# STM32L496AEI6 register map
File version: 1.0
Registers are 32-bit, access not given, reset 0x0 unless marked. A register's access mark holds for its fields unless they carry their own. Offsets are from the block's base; [hi:lo] are bit positions; {n}, {i} and the like mark numbered series; 'fields as' and 'values as' point back to an identical list.

## SAI1
Base 0x40015400
Same registers: SAI2 0x40015800
0x00 GCR
  [5:4] SYNCOUT, [31:2] s, [1:0] SYNCIN
0x04 CR1A
  [23:20] MCKDIV, [19] NODIV, [17] DMAEN, [16] SAIEN, [13] OUTDRIV, [12] MONO, [11:10] SYNCEN, [9] CKSTR, [8] LSBFIRST, [7:5] DS, [31:4] s, [3:2] PRTCFG, [1:0] MODE
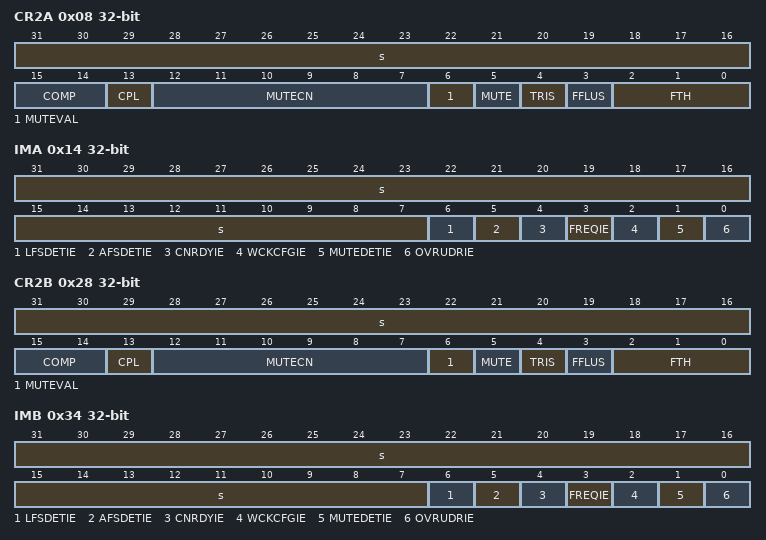
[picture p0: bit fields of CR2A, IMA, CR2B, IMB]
0x08 CR2A
  [31:16] s, [15:14] COMP, [13] CPL, [12:7] MUTECN, [6] MUTEVAL, [5] MUTE, [4] TRIS, [3] FFLUS, [2:0] FTH
0x0C FRCRA
  [18] FSOFF, [17] FSPOL, [16] FSDEF, [31:15] s, [14:8] FSALL, [7:0] FRL
0x10 SLOTRA
  [31:16] SLOTEN, [11:8] NBSLOT, [7:6] SLOTSZ, [15:5] s, [4:0] FBOFF
0x14 IMA
  [31:7] s, [6] LFSDETIE, [5] AFSDETIE, [4] CNRDYIE, [3] FREQIE, [2] WCKCFGIE, [1] MUTEDETIE, [0] OVRUDRIE
0x18 SRA
  [18:16] FLVL, [31:7] s, [6] LFSDET, [5] AFSDET, [4] CNRDY, [3] FREQ, [2] WCKCFG, [1] MUTEDET, [0] OVRUDR
0x1C CLRFRA
  [6] CLFSDET, [5] CAFSDET, [4] CCNRDY, [31:3] s, [2] CWCKCFG, [1] CMUTEDET, [0] COVRUDR
0x20 DRA
  [31:0] DATA
0x24 CR1B
  fields as CR1A
0x28 CR2B
  fields as CR2A
0x2C FRCRB
  fields as FRCRA
0x30 SLOTRB
  [31:16] SLOTEN, [11:8] NBSLOT, [7:6] SLOTSZ, [15:5] s, [4:0] FBOFF
0x34 IMB
  fields as IMA
0x38 SRB
  fields as SRA
0x3C CLRFRB
  fields as CLRFRA
0x40 DRB
  [31:0] DATA

## DFSDM1
Base 0x40016000
0x00 CH0CFGR1
  [31] DFSDMEN, [30] CKOUTSRC, [23:16] CKOUTDIV, [15:14] DATPACK, [13:12] DATMPX, [8] CHINSEL, [7] CHEN, [6] CKABEN, [5] SCDEN, [29:4] s, [3:2] SPICKSEL, [1:0] SITP
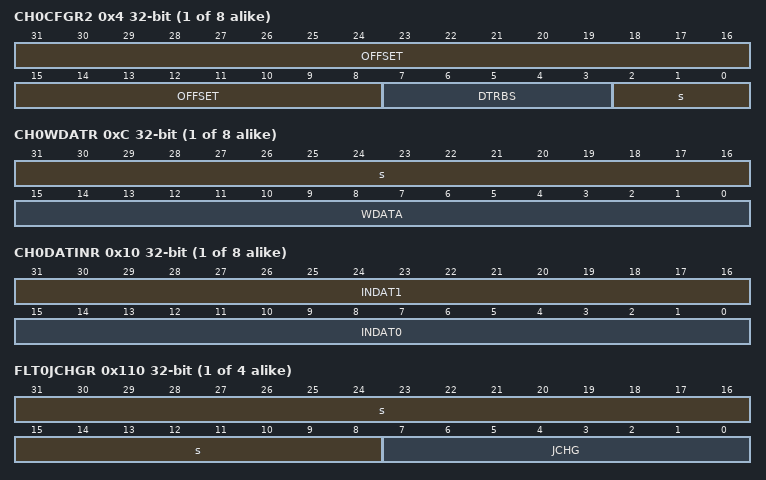
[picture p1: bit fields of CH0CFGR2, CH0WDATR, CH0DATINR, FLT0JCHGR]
{0x4+0x20*i} CH{i}CFGR2 (i=0..7)
  [31:8] OFFSET, [7:3] DTRBS, [2:0] s
{0x8+0x20*i} CH{i}AWSCDR (i=0..7)
  [23:22] AWFORD, [20:16] AWFOSR, [15:12] BKSCD, [31:8] s, [7:0] SCDT
{0xC+0x20*i} CH{i}WDATR (i=0..7)
  [31:16] s, [15:0] WDATA
{0x10+0x20*i} CH{i}DATINR (i=0..7)
  [31:16] INDAT1, [15:0] INDAT0
{0x0+0x20*i} CH{i}CFGR1 (i=1..7)
  [15:14] DATPACK, [13:12] DATMPX, [8] CHINSEL, [7] CHEN, [6] CKABEN, [5] SCDEN, [31:4] s, [3:2] SPICKSEL, [1:0] SITP
{0x100+0x80*i} FLT{i}CR1 (i=0..3)
  [30] AWFSEL, [29] FAST, [26:24] RCH, [21] RDMAEN, [19] RSYNC, [18] RCONT, [17] RSWSTART, [14:13] JEXTEN, [10:8] JEXTSEL, [5] JDMAEN, [4] JSCAN, [3] JSYNC, [31:2] s, [1] JSWSTART, [0] DFEN
0x104 FLT0CR2
  [23:16] AWDCH, [15:8] EXCH, [31:7] s, [6] CKABIE, [5] SCDIE, [4] AWDIE, [3] ROVRIE, [2] JOVRIE, [1] REOCIE, [0] JEOCIE
0x108 FLT0ISR
  [31:24] SCDF, [23:16] CKABF, [14] RCIP, [13] JCIP, [15:5] s, [4] AWDF, [3] ROVRF, [2] JOVRF, [1] REOCF, [0] JEOCF
0x10C FLT0ICR
  [31:24] CLRSCDF, [23:16] CLRCKABF, [3] CLRROVRF, [2] CLRJOVRF, [15:0] s
{0x110+0x80*i} FLT{i}JCHGR (i=0..3)
  [31:8] s, [7:0] JCHG
{0x114+0x80*i} FLT{i}FCR (i=0..3)
  [31:29] FORD, [25:16] FOSR, [28:8] s, [7:0] IOSR
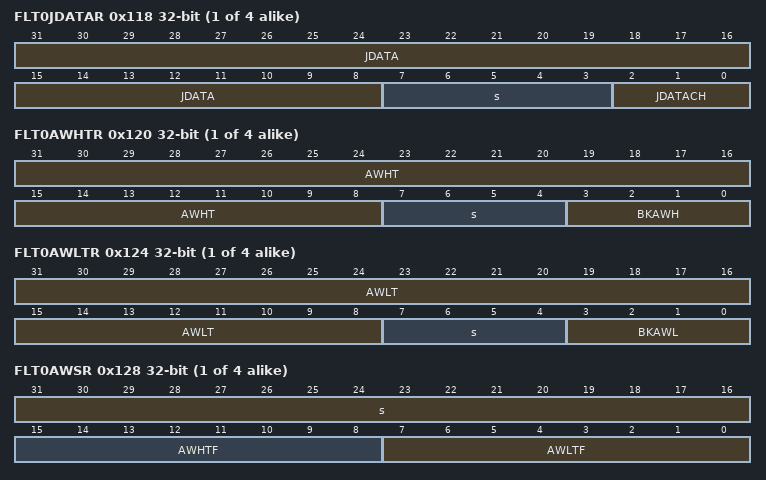
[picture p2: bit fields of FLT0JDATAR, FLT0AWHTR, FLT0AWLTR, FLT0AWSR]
{0x118+0x80*i} FLT{i}JDATAR (i=0..3)
  [31:8] JDATA, [7:3] s, [2:0] JDATACH
{0x11C+0x80*i} FLT{i}RDATAR (i=0..3)
  [31:8] RDATA, [4] RPEND, [7:3] s, [2:0] RDATACH
{0x120+0x80*i} FLT{i}AWHTR (i=0..3)
  [31:8] AWHT, [7:4] s, [3:0] BKAWH
{0x124+0x80*i} FLT{i}AWLTR (i=0..3)
  [31:8] AWLT, [7:4] s, [3:0] BKAWL
{0x128+0x80*i} FLT{i}AWSR (i=0..3)
  [31:16] s, [15:8] AWHTF, [7:0] AWLTF
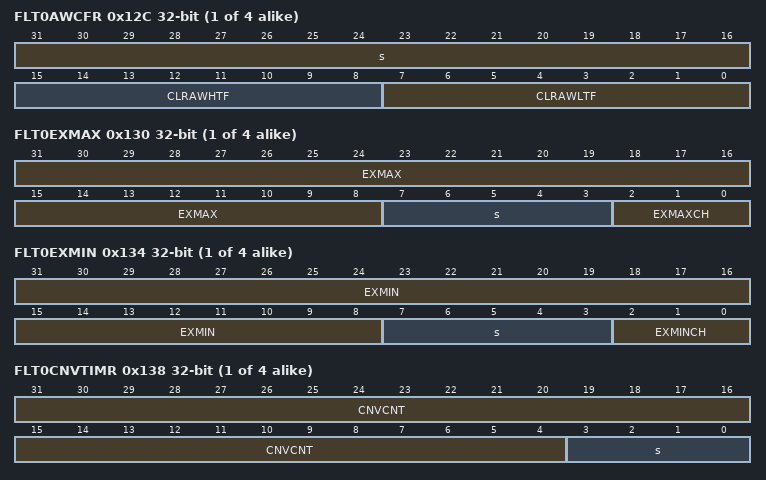
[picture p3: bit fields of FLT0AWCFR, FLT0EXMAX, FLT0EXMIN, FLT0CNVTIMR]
{0x12C+0x80*i} FLT{i}AWCFR (i=0..3)
  [31:16] s, [15:8] CLRAWHTF, [7:0] CLRAWLTF
{0x130+0x80*i} FLT{i}EXMAX (i=0..3)
  [31:8] EXMAX, [7:3] s, [2:0] EXMAXCH
{0x134+0x80*i} FLT{i}EXMIN (i=0..3)
  [31:8] EXMIN, [7:3] s, [2:0] EXMINCH
{0x138+0x80*i} FLT{i}CNVTIMR (i=0..3)
  [31:4] CNVCNT, [3:0] s
{0x104+0x80*i} FLT{i}CR2 (i=1..3)
  [23:16] AWDCH, [15:8] EXCH, [31:5] s, [4] AWDIE, [3] ROVRIE, [2] JOVRIE, [1] REOCIE, [0] JEOCIE
{0x108+0x80*i} FLT{i}ISR (i=1..3)
  [14] RCIP, [13] JCIP, [31:5] s, [4] AWDF, [3] ROVRF, [2] JOVRF, [1] REOCF, [0] JEOCF
{0x10C+0x80*i} FLT{i}ICR (i=1..3)
  [3] CLRROVRF, [2] CLRJOVRF, [31:0] s

## DMA1
Base 0x40020000
Same registers: DMA2 0x40020400
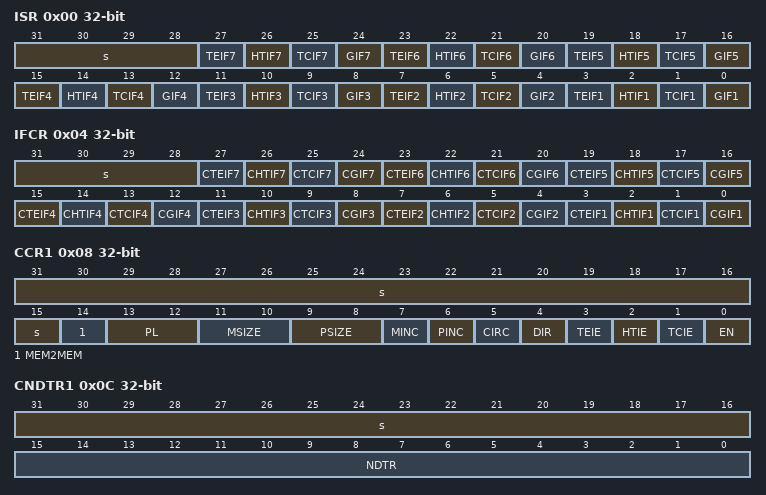
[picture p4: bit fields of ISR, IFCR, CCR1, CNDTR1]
0x00 ISR
  [31:28] s, [4n-1] TEIF{n} (n=1..7), [4n-2] HTIF{n} (n=1..7), [4n-3] TCIF{n} (n=1..7), [4n-4] GIF{n} (n=1..7)
0x04 IFCR
  [31:28] s, [4n-1] CTEIF{n} (n=1..7), [4n-2] CHTIF{n} (n=1..7), [4n-3] CTCIF{n} (n=1..7), [4n-4] CGIF{n} (n=1..7)
0x08 CCR1
  [31:15] s, [14] MEM2MEM, [13:12] PL, [11:10] MSIZE, [9:8] PSIZE, [7] MINC, [6] PINC, [5] CIRC, [4] DIR, [3] TEIE, [2] HTIE, [1] TCIE, [0] EN
0x0C CNDTR1
  [31:16] s, [15:0] NDTR
0x10 CPAR1
  [31:0] PA
{0x0+0x14*i} CMAR{i} (i=1..7)
  [31:0] MA
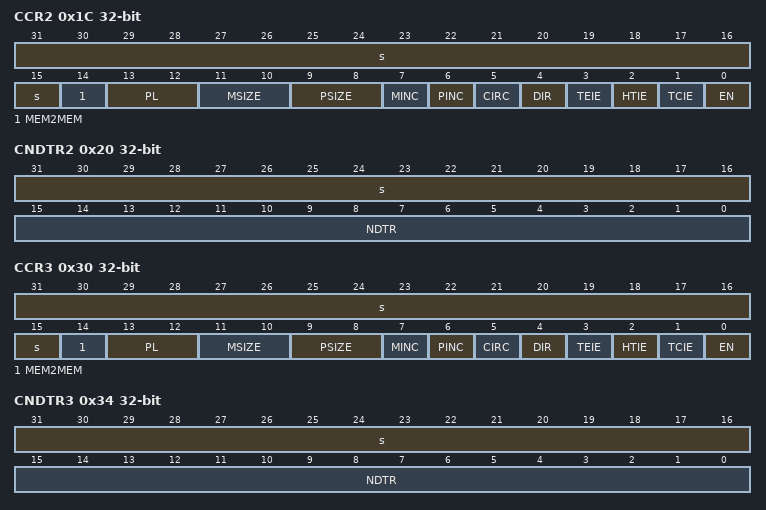
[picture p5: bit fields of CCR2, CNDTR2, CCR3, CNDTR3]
0x1C CCR2
  fields as CCR1
0x20 CNDTR2
  [31:16] s, [15:0] NDTR
0x24 CPAR2
  [31:0] PA
0x30 CCR3
  fields as CCR1
0x34 CNDTR3
  [31:16] s, [15:0] NDTR
0x38 CPAR3
  [31:0] PA
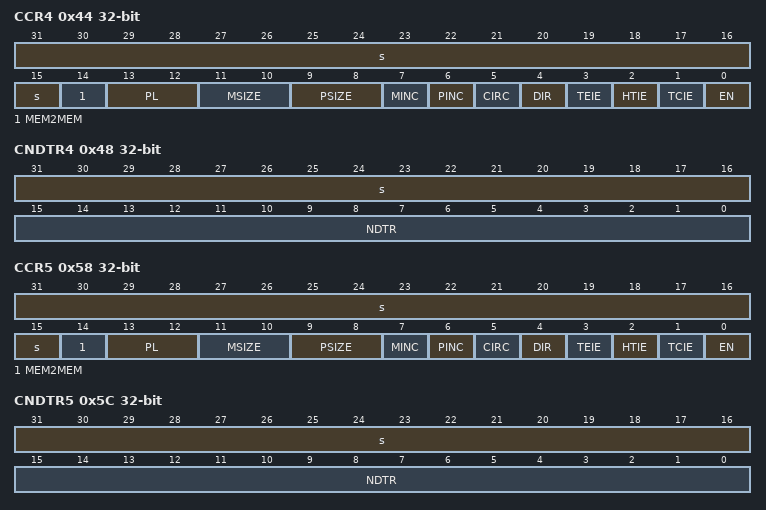
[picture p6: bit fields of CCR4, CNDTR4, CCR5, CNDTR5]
0x44 CCR4
  fields as CCR1
0x48 CNDTR4
  [31:16] s, [15:0] NDTR
0x4C CPAR4
  [31:0] PA
0x58 CCR5
  fields as CCR1
0x5C CNDTR5
  [31:16] s, [15:0] NDTR
0x60 CPAR5
  [31:0] PA
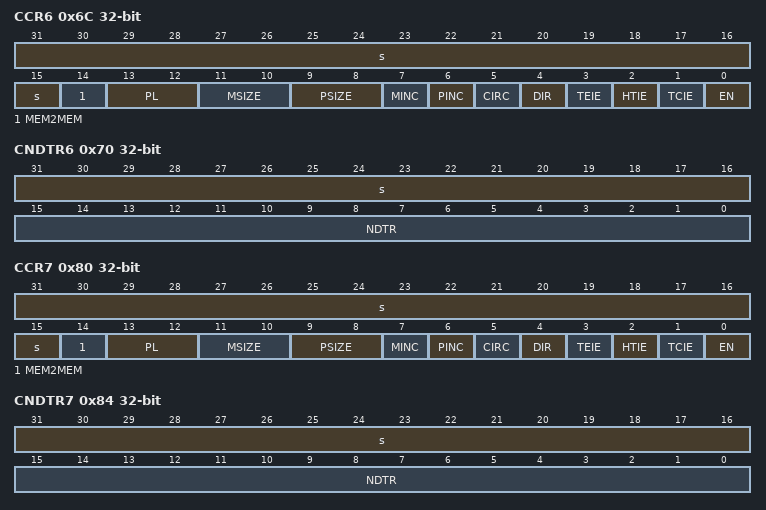
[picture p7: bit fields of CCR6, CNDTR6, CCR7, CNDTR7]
0x6C CCR6
  fields as CCR1
0x70 CNDTR6
  [31:16] s, [15:0] NDTR
0x74 CPAR6
  [31:0] PA
0x80 CCR7
  fields as CCR1
0x84 CNDTR7
  [31:16] s, [15:0] NDTR
0x88 CPAR7
  [31:0] PA
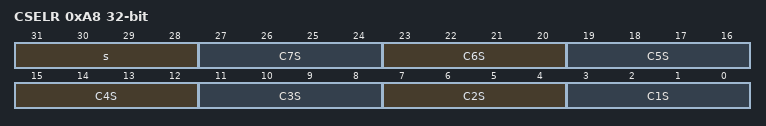
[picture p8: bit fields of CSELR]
0xA8 CSELR
  [31:28] s, [4n-1:4n-4] C{n}S (n=1..7)
